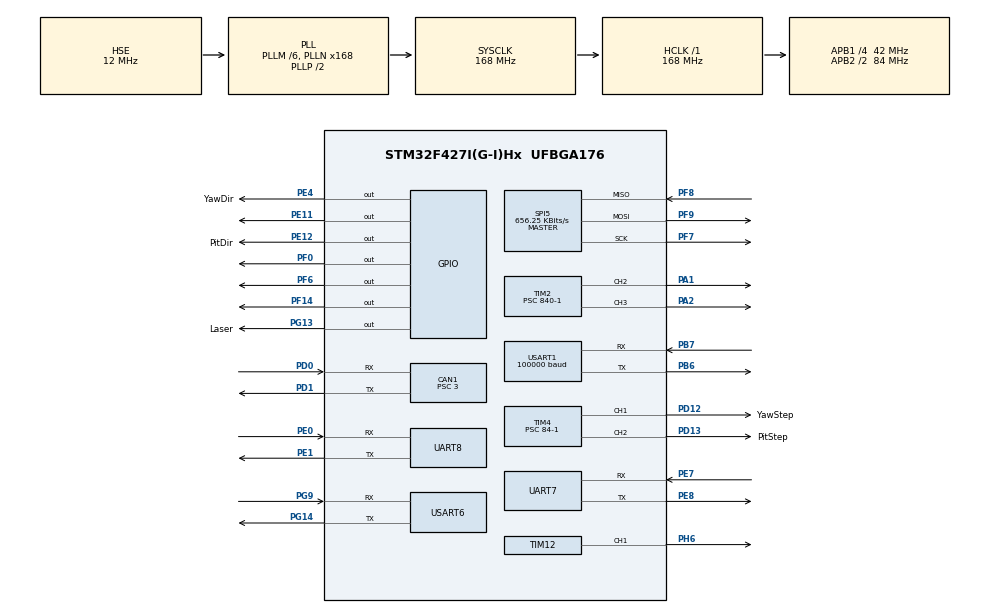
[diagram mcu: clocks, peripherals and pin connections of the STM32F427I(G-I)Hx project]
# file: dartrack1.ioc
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CAN1.BS1=CAN_BS1_6TQ
CAN1.BS2=CAN_BS2_7TQ
CAN1.CalculateBaudRate=1000000
CAN1.CalculateTimeBit=1000
CAN1.CalculateTimeQuantum=71.42857142857143
CAN1.Prescaler=3
Dma.Request0=USART1_RX
Dma.Request1=USART6_RX
Dma.Request2=UART7_RX
Dma.UART7_RX.2.Direction=DMA_PERIPH_TO_MEMORY
Dma.UART7_RX.2.FIFOMode=DMA_FIFOMODE_DISABLE
Dma.UART7_RX.2.Instance=DMA1_Stream3
Dma.UART7_RX.2.MemDataAlignment=DMA_MDATAALIGN_BYTE
Dma.UART7_RX.2.MemInc=DMA_MINC_ENABLE
Dma.UART7_RX.2.Mode=DMA_NORMAL
Dma.UART7_RX.2.PeriphDataAlignment=DMA_PDATAALIGN_BYTE
Dma.UART7_RX.2.PeriphInc=DMA_PINC_DISABLE
Dma.UART7_RX.2.Priority=DMA_PRIORITY_HIGH
Dma.USART1_RX.0.Direction=DMA_PERIPH_TO_MEMORY
Dma.USART1_RX.0.FIFOMode=DMA_FIFOMODE_DISABLE
Dma.USART1_RX.0.Instance=DMA2_Stream2
Dma.USART1_RX.0.MemDataAlignment=DMA_MDATAALIGN_BYTE
Dma.USART1_RX.0.MemInc=DMA_MINC_ENABLE
Dma.USART1_RX.0.Mode=DMA_NORMAL
Dma.USART1_RX.0.PeriphDataAlignment=DMA_PDATAALIGN_BYTE
Dma.USART1_RX.0.PeriphInc=DMA_PINC_DISABLE
Dma.USART1_RX.0.Priority=DMA_PRIORITY_VERY_HIGH
Dma.USART6_RX.1.Direction=DMA_PERIPH_TO_MEMORY
Dma.USART6_RX.1.FIFOMode=DMA_FIFOMODE_DISABLE
Dma.USART6_RX.1.Instance=DMA2_Stream1
Dma.USART6_RX.1.MemDataAlignment=DMA_MDATAALIGN_BYTE
Dma.USART6_RX.1.MemInc=DMA_MINC_ENABLE
Dma.USART6_RX.1.Mode=DMA_NORMAL
Dma.USART6_RX.1.PeriphDataAlignment=DMA_PDATAALIGN_BYTE
Dma.USART6_RX.1.PeriphInc=DMA_PINC_DISABLE
Dma.USART6_RX.1.Priority=DMA_PRIORITY_HIGH
Mcu.Family=STM32F4
Mcu.Name=STM32F427I(G-I)Hx
Mcu.Package=UFBGA176
NVIC.CAN1_RX0_IRQn=true\:1\:0\:true\:false\:true\:true\:true\:true
NVIC.DMA1_Stream3_IRQn=true\:0\:0\:false\:false\:true\:false\:true\:true
NVIC.DMA2_Stream1_IRQn=true\:0\:0\:false\:false\:true\:false\:true\:true
NVIC.DMA2_Stream2_IRQn=true\:0\:0\:true\:false\:true\:false\:true\:true
NVIC.PriorityGroup=NVIC_PRIORITYGROUP_4
NVIC.TIM5_IRQn=true\:2\:0\:true\:false\:true\:true\:true\:true
NVIC.UART7_IRQn=true\:0\:0\:true\:false\:true\:true\:true\:true
NVIC.USART1_IRQn=true\:0\:0\:false\:false\:true\:true\:true\:true
NVIC.USART6_IRQn=true\:0\:0\:false\:false\:true\:true\:true\:true
PA1.GPIO_Speed=GPIO_SPEED_FREQ_VERY_HIGH
PA1.Signal=S_TIM2_CH2
PA13.Mode=Serial_Wire
PA13.Signal=SYS_JTMS-SWDIO
PA14.Mode=Serial_Wire
PA14.Signal=SYS_JTCK-SWCLK
PA2.GPIO_Speed=GPIO_SPEED_FREQ_VERY_HIGH
PA2.Signal=S_TIM2_CH3
PB6.Mode=Asynchronous
PB6.Signal=USART1_TX
PB7.Mode=Asynchronous
PB7.Signal=USART1_RX
PD0.Mode=CAN_Activate
PD0.Signal=CAN1_RX
PD1.Mode=CAN_Activate
PD1.Signal=CAN1_TX
PD12.GPIO_Label=YawStep
PD12.GPIO_Speed=GPIO_SPEED_FREQ_VERY_HIGH
PD12.Signal=S_TIM4_CH1
PD13.GPIO_Label=PitStep
PD13.GPIO_Speed=GPIO_SPEED_FREQ_VERY_HIGH
PD13.Signal=S_TIM4_CH2
PE0.Mode=Asynchronous
PE0.Signal=UART8_RX
PE1.Mode=Asynchronous
PE1.Signal=UART8_TX
PE11.GPIO_Speed=GPIO_SPEED_FREQ_HIGH
PE11.Signal=GPIO_Output
PE12.GPIO_Label=PitDir
PE12.GPIO_Speed=GPIO_SPEED_FREQ_VERY_HIGH
PE12.PinState=GPIO_PIN_RESET
PE12.Signal=GPIO_Output
PE4.GPIO_Label=YawDir
PE4.GPIO_Speed=GPIO_SPEED_FREQ_VERY_HIGH
PE4.PinState=GPIO_PIN_RESET
PE4.Signal=GPIO_Output
PE7.Mode=Asynchronous
PE7.Signal=UART7_RX
PE8.Mode=Asynchronous
PE8.Signal=UART7_TX
PF0.GPIO_Speed=GPIO_SPEED_FREQ_VERY_HIGH
PF0.PinState=GPIO_PIN_RESET
PF0.Signal=GPIO_Output
PF14.GPIO_Speed=GPIO_SPEED_FREQ_VERY_HIGH
PF14.Signal=GPIO_Output
PF6.GPIO_Speed=GPIO_SPEED_FREQ_VERY_HIGH
PF6.PinState=GPIO_PIN_SET
PF6.Signal=GPIO_Output
PF7.Mode=Full_Duplex_Master
PF7.Signal=SPI5_SCK
PF8.Mode=Full_Duplex_Master
PF8.Signal=SPI5_MISO
PF9.Mode=Full_Duplex_Master
PF9.Signal=SPI5_MOSI
PG13.GPIO_Label=Laser
PG13.GPIO_Speed=GPIO_SPEED_FREQ_VERY_HIGH
PG13.Signal=GPIO_Output
PG14.Mode=Asynchronous
PG14.Signal=USART6_TX
PG9.Mode=Asynchronous
PG9.Signal=USART6_RX
PH0/OSC_IN.Mode=HSE-External-Oscillator
PH0/OSC_IN.Signal=RCC_OSC_IN
PH1/OSC_OUT.Mode=HSE-External-Oscillator
PH1/OSC_OUT.Signal=RCC_OSC_OUT
PH6.Signal=S_TIM12_CH1
ProjectManager.HeapSize=0x200
ProjectManager.StackSize=0x400
ProjectManager.TargetToolchain=STM32CubeIDE
RCC.48MHZClocksFreq_Value=84000000
RCC.AHBFreq_Value=168000000
RCC.APB1CLKDivider=RCC_HCLK_DIV4
RCC.APB1Freq_Value=42000000
RCC.APB1TimFreq_Value=84000000
RCC.APB2CLKDivider=RCC_HCLK_DIV2
RCC.APB2Freq_Value=84000000
RCC.APB2TimFreq_Value=168000000
RCC.CortexFreq_Value=168000000
RCC.HCLKFreq_Value=168000000
RCC.HSE_VALUE=12000000
RCC.HSI_VALUE=16000000
RCC.LSE_VALUE=32768
RCC.PLLM=6
RCC.PLLN=168
RCC.PLLSourceVirtual=RCC_PLLSOURCE_HSE
RCC.SYSCLKFreq_VALUE=168000000
RCC.SYSCLKSource=RCC_SYSCLKSOURCE_PLLCLK
RCC.VCOOutputFreq_Value=336000000
SH.S_TIM12_CH1.0=TIM12_CH1,PWM Generation1 CH1
SH.S_TIM2_CH2.0=TIM2_CH2,PWM Generation2 CH2
SH.S_TIM2_CH3.0=TIM2_CH3,PWM Generation3 CH3
SH.S_TIM4_CH1.0=TIM4_CH1,PWM Generation1 CH1
SH.S_TIM4_CH2.0=TIM4_CH2,PWM Generation2 CH2
SPI5.BaudRatePrescaler=SPI_BAUDRATEPRESCALER_128
SPI5.CalculateBaudRate=656.25 KBits/s
SPI5.Direction=SPI_DIRECTION_2LINES
SPI5.Mode=SPI_MODE_MASTER
SPI5.VirtualType=VM_MASTER
TIM12.Channel-PWM\ Generation1\ CH1=TIM_CHANNEL_1
TIM12.Prescaler=84-1
TIM2.Channel-PWM\ Generation2\ CH2=TIM_CHANNEL_2
TIM2.Channel-PWM\ Generation3\ CH3=TIM_CHANNEL_3
TIM2.Period=2000-1
TIM2.Prescaler=840-1
TIM2.Pulse-PWM\ Generation2\ CH2=50
TIM2.Pulse-PWM\ Generation3\ CH3=50
TIM4.Channel-PWM\ Generation1\ CH1=TIM_CHANNEL_1
TIM4.Channel-PWM\ Generation2\ CH2=TIM_CHANNEL_2
TIM4.Period=2000-1
TIM4.Prescaler=84-1
TIM4.Pulse-PWM\ Generation1\ CH1=5
TIM5.Period=2000-1
TIM5.Prescaler=84-1
UART7.VirtualMode=Asynchronous
UART8.VirtualMode=Asynchronous
USART1.BaudRate=100000
USART1.Mode=MODE_RX
USART1.Parity=PARITY_EVEN
USART1.VirtualMode=VM_ASYNC
USART1.WordLength=WORDLENGTH_9B
USART6.VirtualMode=VM_ASYNC
VP_TIM12_VS_ClockSourceINT.Mode=Internal
VP_TIM2_VS_ClockSourceINT.Mode=Internal
VP_TIM4_VS_ClockSourceINT.Mode=Internal
VP_TIM5_VS_ClockSourceINT.Mode=Internal
board=custom

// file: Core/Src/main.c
/* USER CODE BEGIN Header */
/**
  ******************************************************************************
  * @file           : main.c
  * @brief          : Main program body
  ******************************************************************************
  * @attention
  *
  * Copyright (c) 2023 STMicroelectronics.
  * All rights reserved.
  *
  * This software is licensed under terms that can be found in the LICENSE file
  * in the root directory of this software component.
  * If no LICENSE file comes with this software, it is provided AS-IS.
  *
  ******************************************************************************
  */
/* USER CODE END Header */
#include "main.h"
#include "can.h"
#include "dma.h"
#include "spi.h"
#include "tim.h"
#include "usart.h"
#include "gpio.h"

/* USER CODE BEGIN Includes */
// #include "bsp_imu.h"
#include "task.hpp"
/* USER CODE END Includes */

void SystemClock_Config(void);

int main(void)
{

  /* MCU Configuration--------------------------------------------------------*/

  /* Reset of all peripherals, Initializes the Flash interface and the Systick. */
  HAL_Init();

  /* Configure the system clock */
  SystemClock_Config();

  /* Initialize all configured peripherals */
  MX_GPIO_Init();
  MX_DMA_Init();
  MX_TIM5_Init();
  MX_TIM4_Init();
  MX_TIM2_Init();
  MX_USART1_UART_Init();
  MX_CAN1_Init();
  MX_SPI5_Init();
  MX_USART6_UART_Init();
  MX_UART8_Init();
  MX_UART7_Init();
  MX_TIM12_Init();
  /* USER CODE BEGIN 2 */
  TaskInit();
  //mpu_device_init();
  //init_quaternion();
  // CAN_FilterInit(&hcan1);
  // HAL_CAN_Start(&hcan1);
  // HAL_CAN_ActivateNotification(&hcan1,CAN_IT_RX_FIFO0_MSG_PENDING);
  // Motor_YAW_Init();
  // Dbus_Init();
  // HAL_TIM_PWM_Start(&htim2, TIM_CHANNEL_3);//舵机PWM
  // HAL_TIM_Base_Start_IT(&htim5);
//  HAL_TIM_Base_Start_IT(&htim4);
 // HAL_TIM_Base_Start_IT(&htim2);
  /* USER CODE END 2 */

  /* Infinite loop */
  while (1)
  {

  }
}

void SystemClock_Config(void)
{
  RCC_OscInitTypeDef RCC_OscInitStruct = {0};
  RCC_ClkInitTypeDef RCC_ClkInitStruct = {0};

  /** Configure the main internal regulator output voltage
  */
  __HAL_RCC_PWR_CLK_ENABLE();
  __HAL_PWR_VOLTAGESCALING_CONFIG(PWR_REGULATOR_VOLTAGE_SCALE1);

  /** Initializes the RCC Oscillators according to the specified parameters
  * in the RCC_OscInitTypeDef structure.
  */
  RCC_OscInitStruct.OscillatorType = RCC_OSCILLATORTYPE_HSE;
  RCC_OscInitStruct.HSEState = RCC_HSE_ON;
  RCC_OscInitStruct.PLL.PLLState = RCC_PLL_ON;
  RCC_OscInitStruct.PLL.PLLSource = RCC_PLLSOURCE_HSE;
  RCC_OscInitStruct.PLL.PLLM = 6;
  RCC_OscInitStruct.PLL.PLLN = 168;
  RCC_OscInitStruct.PLL.PLLP = RCC_PLLP_DIV2;
  RCC_OscInitStruct.PLL.PLLQ = 4;
  if (HAL_RCC_OscConfig(&RCC_OscInitStruct) != HAL_OK)
  {
    Error_Handler();
  }

  /** Initializes the CPU, AHB and APB buses clocks
  */
  RCC_ClkInitStruct.ClockType = RCC_CLOCKTYPE_HCLK|RCC_CLOCKTYPE_SYSCLK
                              |RCC_CLOCKTYPE_PCLK1|RCC_CLOCKTYPE_PCLK2;
  RCC_ClkInitStruct.SYSCLKSource = RCC_SYSCLKSOURCE_PLLCLK;
  RCC_ClkInitStruct.AHBCLKDivider = RCC_SYSCLK_DIV1;
  RCC_ClkInitStruct.APB1CLKDivider = RCC_HCLK_DIV4;
  RCC_ClkInitStruct.APB2CLKDivider = RCC_HCLK_DIV2;

  if (HAL_RCC_ClockConfig(&RCC_ClkInitStruct, FLASH_LATENCY_5) != HAL_OK)
  {
    Error_Handler();
  }
}

void Error_Handler(void)
{
  __disable_irq();
  while (1)
  {
  }
}
